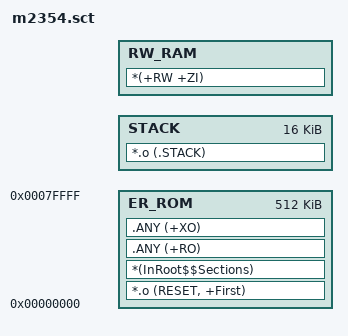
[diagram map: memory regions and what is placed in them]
#! armclang -E --target=arm-arm-none-eabi -mcpu=cortex-m23 -xc

#define STACK_SIZE        0x00004000

/*----------------------------------------------------------------------------
  Scatter Region definition
 *----------------------------------------------------------------------------*/
LR_ROM 0 0x80000 {
    ER_ROM 0 0x80000 {
        *.o (RESET, +First)
        *(InRoot$$Sections)
        .ANY (+RO)
        .ANY (+XO)
    }

    STACK +0 ALIGN 32 STACK_SIZE {
        *.o (.STACK)
    }

    RW_RAM AlignExpr(+0,8) {
        *(+RW +ZI)
    }
}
